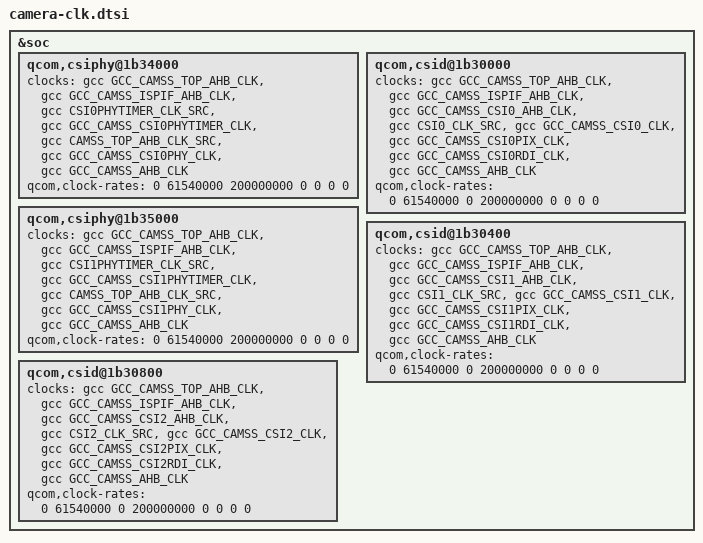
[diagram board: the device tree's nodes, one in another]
&soc {
	qcom,csiphy@1b34000 {
		clocks = <&gcc GCC_CAMSS_TOP_AHB_CLK>,
			<&gcc GCC_CAMSS_ISPIF_AHB_CLK>,
			<&gcc CSI0PHYTIMER_CLK_SRC>,
			<&gcc GCC_CAMSS_CSI0PHYTIMER_CLK>,
			<&gcc CAMSS_TOP_AHB_CLK_SRC>,
			<&gcc GCC_CAMSS_CSI0PHY_CLK>,
			<&gcc GCC_CAMSS_AHB_CLK>;
		clock-names = "camss_top_ahb_clk", "ispif_ahb_clk",
			"csiphy_timer_src_clk", "csiphy_timer_clk",
			"camss_ahb_src", "csi_phy_clk",
			"camss_ahb_clk";
		qcom,clock-rates = <0 61540000 200000000 0 0 0 0>;
	};

	qcom,csiphy@1b35000 {
		clocks = <&gcc GCC_CAMSS_TOP_AHB_CLK>,
			<&gcc GCC_CAMSS_ISPIF_AHB_CLK>,
			<&gcc CSI1PHYTIMER_CLK_SRC>,
			<&gcc GCC_CAMSS_CSI1PHYTIMER_CLK>,
			<&gcc CAMSS_TOP_AHB_CLK_SRC>,
			<&gcc GCC_CAMSS_CSI1PHY_CLK>,
			<&gcc GCC_CAMSS_AHB_CLK>;
		clock-names = "camss_top_ahb_clk", "ispif_ahb_clk",
			"csiphy_timer_src_clk", "csiphy_timer_clk",
			"camss_ahb_src", "csi_phy_clk",
			"camss_ahb_clk";
		qcom,clock-rates = <0 61540000 200000000 0 0 0 0>;
	};

	qcom,csid@1b30000  {
		clocks = <&gcc GCC_CAMSS_TOP_AHB_CLK>,
			<&gcc GCC_CAMSS_ISPIF_AHB_CLK>,
			<&gcc GCC_CAMSS_CSI0_AHB_CLK>,
			<&gcc CSI0_CLK_SRC>,
			<&gcc GCC_CAMSS_CSI0_CLK>,
			<&gcc GCC_CAMSS_CSI0PIX_CLK>,
			<&gcc GCC_CAMSS_CSI0RDI_CLK>,
			<&gcc GCC_CAMSS_AHB_CLK>;
		clock-names = "camss_top_ahb_clk",
			"ispif_ahb_clk", "csi_ahb_clk", "csi_src_clk",
			"csi_clk",  "csi_pix_clk",
			"csi_rdi_clk", "camss_ahb_clk";
		qcom,clock-rates = <0 61540000 0 200000000 0 0 0 0>;
	};

	qcom,csid@1b30400 {
		clocks = <&gcc GCC_CAMSS_TOP_AHB_CLK>,
			<&gcc GCC_CAMSS_ISPIF_AHB_CLK>,
			<&gcc GCC_CAMSS_CSI1_AHB_CLK>,
			<&gcc CSI1_CLK_SRC>,
			<&gcc GCC_CAMSS_CSI1_CLK>,
			<&gcc GCC_CAMSS_CSI1PIX_CLK>,
			<&gcc GCC_CAMSS_CSI1RDI_CLK>,
			<&gcc GCC_CAMSS_AHB_CLK>;
		clock-names = "camss_top_ahb_clk",
			"ispif_ahb_clk", "csi_ahb_clk", "csi_src_clk",
			"csi_clk", "csi_pix_clk",
			"csi_rdi_clk", "camss_ahb_clk";
		qcom,clock-rates = <0 61540000 0 200000000 0 0 0 0>;
	};

	qcom,csid@1b30800 {
		clocks = <&gcc GCC_CAMSS_TOP_AHB_CLK>,
			<&gcc GCC_CAMSS_ISPIF_AHB_CLK>,
			<&gcc GCC_CAMSS_CSI2_AHB_CLK>,
			<&gcc CSI2_CLK_SRC>,
			<&gcc GCC_CAMSS_CSI2_CLK>,
			<&gcc GCC_CAMSS_CSI2PIX_CLK>,
			<&gcc GCC_CAMSS_CSI2RDI_CLK>,
			<&gcc GCC_CAMSS_AHB_CLK>;
		clock-names = "camss_top_ahb_clk",
			"ispif_ahb_clk", "csi_ahb_clk", "csi_src_clk",
			"csi_clk", "csi_pix_clk",
			"csi_rdi_clk", "camss_ahb_clk";
		qcom,clock-rates = <0 61540000 0 200000000 0 0 0 0>;
	};
};
